# ValidSemantic register map
File version: 1
Semantic fixtures
Registers are 32-bit, read-write, reset 0x11 unless marked. A register's access mark holds for its fields unless they carry their own. Offsets are from the block's base; lines under a group give offsets from that group; [hi:lo] are bit positions; {n}, {i} and the like mark numbered series; 'fields as' and 'values as' point back to an identical list; <NAME> marks a mode.

## Memory map
0x00001000 P blocks up to offset 0xC

## P
Base 0x00001000
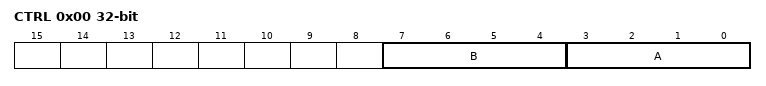
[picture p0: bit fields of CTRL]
0x00 CTRL
  [7:4] B
  [3:0] A
    on read: 0=OFF | on write: 0=START
0x00 VIEW (reset mask 0xFF) (alternate view of CTRL)
0x08 ONCE write-once (reset mask 0xFF) write-1-clears
